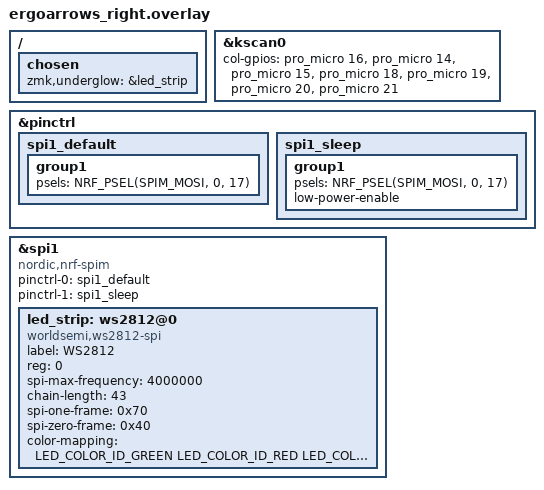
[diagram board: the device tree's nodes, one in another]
#include "ergoarrows.dtsi"
#include <dt-bindings/led/led.h>

/ {
    chosen {
        zmk,underglow = &led_strip;
    };
};

&kscan0 {
    col-gpios
        = <&pro_micro 16 GPIO_ACTIVE_HIGH>
        , <&pro_micro 14 GPIO_ACTIVE_HIGH>
        , <&pro_micro 15 GPIO_ACTIVE_HIGH>
        , <&pro_micro 18 GPIO_ACTIVE_HIGH>
        , <&pro_micro 19 GPIO_ACTIVE_HIGH>
        , <&pro_micro 20 GPIO_ACTIVE_HIGH>
        , <&pro_micro 21 GPIO_ACTIVE_HIGH>
        ;
};

&pinctrl {
    spi1_default: spi1_default {
        group1 {
            psels = <NRF_PSEL(SPIM_MOSI, 0, 17)>;
        };
    };
    spi1_sleep: spi1_sleep {
        group1 {
            psels = <NRF_PSEL(SPIM_MOSI, 0, 17)>;
            low-power-enable;
        };
    };
};

&spi1 {
    compatible = "nordic,nrf-spim";
    status = "okay";
    pinctrl-0 = <&spi1_default>;
    pinctrl-1 = <&spi1_sleep>;
    pinctrl-names = "default", "sleep";
    led_strip: ws2812@0 {
        compatible = "worldsemi,ws2812-spi";
        label = "WS2812";
        reg = <0>;
        spi-max-frequency = <4000000>;
        chain-length = <43>;
        spi-one-frame = <0x70>;
        spi-zero-frame = <0x40>;
        color-mapping = <LED_COLOR_ID_GREEN
                         LED_COLOR_ID_RED
                         LED_COLOR_ID_BLUE>;
    };
};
